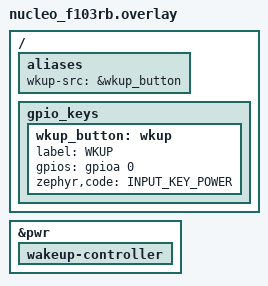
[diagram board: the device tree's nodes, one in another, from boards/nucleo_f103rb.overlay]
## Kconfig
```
# SPDX-FileCopyrightText: Copyright (c) 2026 STMicroelectronics
# SPDX-License-Identifier: Apache-2.0

source "Kconfig.zephyr"

choice
	prompt "Sample scenario"
	default SAMPLE_SCENARIO_POWEROFF

config SAMPLE_SCENARIO_POWEROFF
	bool "Power Off"
	select POWEROFF
	help
	  Demonstrate usage of wake-up pins in Poweroff low-power state.
	  In this scenario, the SoC enters a deep low-power state (e.g., "Shutdown" on STM32C0)
	  and is powered off completely; a wake-up pin is then used to wake the SoC which starts
	  execution as if it had just been reset.

config SAMPLE_SCENARIO_S2RAM
	bool "Suspend to RAM"
	depends on $(dt_compat_any_has_prop,$(DT_COMPAT_ZEPHYR_POWER_STATE),power-state-name,suspend-to-ram)
	depends on SOC_SERIES_STM32WBAX  # Needs SoC-specific support; only implemented on WBA today
	select PM
	select PM_DEVICE
	select PM_DEVICE_RUNTIME
	select PM_DEVICE_SYSTEM_MANAGED
	help
	  Demonstrate usage of wake-up pins in S2RAM (suspend-to-RAM) low-power states.
	  In this scenario, wake-up pins are used to wake the SoC and trigger a GPIO callback.

endchoice

config SAMPLE_BUSY_WAIT_TIME_MS
	int "Busy-wait time (in milliseconds)"
	default 4000 if SAMPLE_SCENARIO_POWEROFF
	default 1000 if SAMPLE_SCENARIO_S2RAM
	help
	  Amount of time the system will busy-wait before entry in low-power state.
	  In the "Power Off" scenario, this delay elapses once then the system powers off.
	  In the "Suspend to RAM" scenario, this delay elapses before waiting for a button press.

config SAMPLE_BUTTON_PRESS_TIMEOUT_MS
	int "Button press timeout (in milliseconds)"
	default 5000
	depends on SAMPLE_SCENARIO_S2RAM
	help
	  Amount of time the system will wait for a button press before a timeout occurs.
	  This timeout will wake the system if the button is not pressed within the specified time.
	  Only relevant in the "Suspend to RAM" scenario.
```

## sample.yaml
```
sample:
  name: GPIO As A Wake-up Pin Source
tests:
  sample.boards.stm32.power_mgmt.wkup_pins:
    build_only: true
    filter: dt_enabled_alias_with_parent_compat("wkup-src",
      "gpio-keys") and dt_compat_enabled("st,stm32-pwr")
    platform_allow:
      - nucleo_c092rc
      - nucleo_f103rb
      - nucleo_g031k8
      - nucleo_l152re
      - nucleo_l4r5zi
      - nucleo_u575zi_q
      - nucleo_u5a5zj_q
      - nucleo_wba55cg
      - nucleo_wba65ri
      - nucleo_wl55jc
      - stm32l1_disco
    integration_platforms:
      - nucleo_l4r5zi
```

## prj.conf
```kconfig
# SPDX-FileCopyrightText: Copyright The Zephyr Project Contributors
# SPDX-License-Identifier: Apache-2.0

CONFIG_GPIO=y
CONFIG_HWINFO=y
CONFIG_STM32_WKUP_PINS=y
```

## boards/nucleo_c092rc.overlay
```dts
/*
 * Copyright (c) 2024 STMicroelectronics
 * Copyright (c) 2025 Thomas Stranger
 *
 * SPDX-License-Identifier: Apache-2.0
 */

/ {
	aliases {
		wkup-src = &user_button;
	};
};

&pwr {
	wakeup-controller {
		status = "okay";
	};
};
```

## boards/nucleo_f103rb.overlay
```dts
/*
 * Copyright (c) 2025 Oleh Kravchenko <oleh@kaa.org.ua>
 *
 * SPDX-License-Identifier: Apache-2.0
 */

/ {
	aliases {
		wkup-src = &wkup_button;
	};

	gpio_keys {
		/*
		 * PA0 is not connected to any button: you
		 * must connect it to Vdd using a jumper wire.
		 * (N.B.: PA0 is Arduino "A0"; Vdd is "+3.3V")
		 */
		wkup_button: wkup {
			label = "WKUP";
			gpios = <&gpioa 0 (GPIO_ACTIVE_HIGH | GPIO_PULL_DOWN)>;
			zephyr,code = <INPUT_KEY_POWER>;
		};
	};
};

&pwr {
	wakeup-controller {
		status = "okay";
	};
};
```

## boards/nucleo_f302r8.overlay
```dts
/*
 * Copyright (c) 2025 Enes Albay <albayenes@gmail.com>
 *
 * SPDX-License-Identifier: Apache-2.0
 */

/ {
	aliases {
		wkup-src = &wkup_button;
	};

	gpio_keys {
		wkup_button: wkup {
			label = "WKUP";
			/*
			 * PA0 is not connected to any button: you must connect it to VDD (+3.3V)
			 * using a jumper wire. For example, wiring PA0 CN7[28] to VDD CN7[16]
			 */
			gpios = <&gpioa 0 (GPIO_ACTIVE_HIGH | GPIO_PULL_DOWN)>;
			zephyr,code = <INPUT_KEY_POWER>;
		};
	};
};

&pwr {
	status = "okay";
};
```

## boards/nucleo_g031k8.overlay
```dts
/*
 * Copyright (c) 2025 A Labs GmbH
 *
 * SPDX-License-Identifier: Apache-2.0
 */

#include <zephyr/dt-bindings/input/input-event-codes.h>

/ {
	/* the board has no actual button, you need to connect PA0 to GND with a jumper wire */
	gpio_keys {
		compatible = "gpio-keys";

		user_button: button {
			label = "User";
			gpios = <&gpioa 0 (GPIO_PULL_UP | GPIO_ACTIVE_LOW)>;
			zephyr,code = <INPUT_KEY_0>;
		};
	};

	aliases {
		wkup-src = &user_button;
	};
};

&pwr {
	wakeup-controller {
		status = "okay";
	};
};
```

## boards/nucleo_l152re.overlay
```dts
/*
 * Copyright (c) 2025 Oleh Kravchenko <oleh@kaa.org.ua>
 *
 * SPDX-License-Identifier: Apache-2.0
 */

/ {
	aliases {
		wkup-src = &user_button;
	};
};

&pwr {
	status = "okay";
};
```

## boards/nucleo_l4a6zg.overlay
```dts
/*
 * Copyright (c) 2026 Witekio
 *
 * SPDX-License-Identifier: Apache-2.0
 */

/ {
	aliases {
		wkup-src = &user_button;
	};
};

&pwr {
	wakeup-controller {
		status = "okay";
	};
};
```

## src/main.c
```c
/*
 * Copyright (c) 2024 STMicroelectronics
 *
 * SPDX-License-Identifier: Apache-2.0
 */

#include <zephyr/kernel.h>
#include <zephyr/device.h>
#include <zephyr/devicetree.h>
#include <zephyr/drivers/gpio.h>
#include <zephyr/drivers/hwinfo.h>
#include <zephyr/sys/printk.h>
#include <zephyr/sys/poweroff.h>
#include <zephyr/dt-bindings/gpio/stm32-gpio.h>

#define WKUP_SRC_NODE DT_ALIAS(wkup_src)
#if !DT_NODE_HAS_STATUS_OKAY(WKUP_SRC_NODE)
#error "Unsupported board: wkup_src devicetree alias is not defined"
#endif

static const struct gpio_dt_spec button = GPIO_DT_SPEC_GET(WKUP_SRC_NODE, gpios);

static const struct gpio_dt_spec led = GPIO_DT_SPEC_GET(DT_ALIAS(led0), gpios);

#if defined(CONFIG_SAMPLE_SCENARIO_S2RAM)
static K_SEM_DEFINE(button_sem, 0, 1);
static struct gpio_callback button_cb_data;

void button_press_cb(const struct device *port, struct gpio_callback *cb, gpio_port_pins_t pins)
{
	ARG_UNUSED(port);
	ARG_UNUSED(cb);
	ARG_UNUSED(pins);

	printk("Hi from button press callback!\n");
	k_sem_give(&button_sem);
}

int configure_irq_callback(void)
{
	int res;

	gpio_init_callback(&button_cb_data, button_press_cb, BIT(button.pin));

	res = gpio_add_callback_dt(&button, &button_cb_data);
	if (res < 0) {
		printk("Failed to add callback for %s pin %d: %d\n",
		       button.port->name, button.pin, res);
		return res;
	}

	res = gpio_pin_interrupt_configure_dt(&button, GPIO_INT_EDGE_TO_ACTIVE);
	if (res < 0) {
		printk("Failed to configure %s pin %d as interrupt source: %d\n",
		       button.port->name, button.pin, res);
		return res;
	}

	return 0;
}
#endif /* CONFIG_SAMPLE_SCENARIO_S2RAM */

int main(void)
{
	uint32_t reset_cause;
	int res;

	res = hwinfo_get_reset_cause(&reset_cause);
	if (res == 0) {
		if (reset_cause & RESET_LOW_POWER_WAKE) {
			printk("Reset from low-power state detected.\n");
			printk("Continuing sample execution...\n");
		}
	} else {
		printk("Failed to get reset cause: %d\n", res);
	}

	printk("\nWake-up button is connected to %s pin %d\n", button.port->name, button.pin);

	__ASSERT_NO_MSG(gpio_is_ready_dt(&led));
	gpio_pin_configure_dt(&led, GPIO_OUTPUT_ACTIVE);
	gpio_pin_set(led.port, led.pin, 1);

	/* Setup button GPIO pin as a source for exiting Poweroff */
	res = gpio_pin_configure_dt(&button, GPIO_INPUT | STM32_GPIO_WKUP);
	if (res < 0) {
		printk("Failed to configure %s pin %d as wake-up pin: %d\n",
		       button.port->name, button.pin, res);
		printk("Are you sure this pin is a valid wake-up pin?\n");
		return 0;
	}

	const char *pre_sleep_prompt = "Will wait %d ms before powering the system off\n";

#if defined(CONFIG_SAMPLE_SCENARIO_S2RAM)
	res = configure_irq_callback();
	if (res < 0) {
		printk("Failed to install button press callback: %d\n", res);
		return 0;
	}

	pre_sleep_prompt = "Busy-looping until low-power entry for %d ms...\n";
#endif /* CONFIG_SAMPLE_SCENARIO_S2RAM */

	while (1) {
		printk(pre_sleep_prompt, CONFIG_SAMPLE_BUSY_WAIT_TIME_MS);
		k_busy_wait(CONFIG_SAMPLE_BUSY_WAIT_TIME_MS * USEC_PER_MSEC);

#if defined(CONFIG_SAMPLE_SCENARIO_POWEROFF)
		printk("Powering off\n");
		printk("Press the user button to power the system on\n\n");

		sys_poweroff();
		/* Will remain powered off until wake-up or reset button is pressed */

		return 0;
#endif /* CONFIG_SAMPLE_SCENARIO_POWEROFF */
#if defined(CONFIG_SAMPLE_SCENARIO_S2RAM)
		printk("Waiting up to %d ms in low-power state for button press...\n",
			CONFIG_SAMPLE_BUTTON_PRESS_TIMEOUT_MS);

		res = k_sem_take(&button_sem, K_MSEC(CONFIG_SAMPLE_BUTTON_PRESS_TIMEOUT_MS));
		printk("\n");

		/* HACK: GPIO driver doesn't survive an S2RAM cycle yet... */
		(void)gpio_pin_configure_dt(&button, GPIO_INPUT | STM32_GPIO_WKUP);
		(void)gpio_pin_interrupt_configure_dt(&button, GPIO_INT_EDGE_TO_ACTIVE);

		if (res == 0) {
			printk("Acquired button press semaphore.\n");
		} else if (res == -EAGAIN) {
			printk("Button was not pressed before timeout.\n");
			printk("Waiting for button press before continuing...\n");
			(void)k_sem_take(&button_sem, K_FOREVER);
		} else {
			printk("Unexpected error occurred: %d\n", res);
			break;
		}
#endif /* CONFIG_SAMPLE_SCENARIO_S2RAM */
	}

	return 0;
}
```
